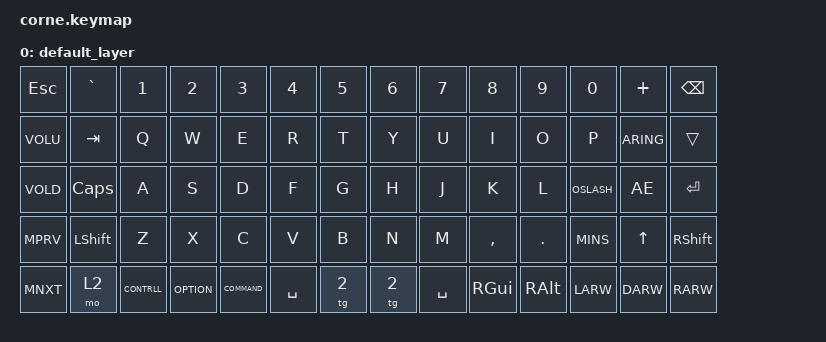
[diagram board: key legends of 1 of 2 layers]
/*
 * Copyright (c) 2020 The ZMK Contributors
 *
 * SPDX-License-Identifier: MIT
 */

#include <behaviors.dtsi>
#include <dt-bindings/zmk/keys.h>
#include <dt-bindings/zmk/bt.h>

#include <behaviors.dtsi>
#include <dt-bindings/zmk/keys.h>
#include <dt-bindings/zmk/bt.h>

/ {
        keymap {
                compatible = "zmk,keymap";

                default_layer {
// ------------------------------------------------------------------------------------------------------------
|      |      |      |      |      |      |      |   void   |      |      |      |      |      |      |      |
|      |      |      |      |      |      |      |   void   |      |      |      |      |      |      |      |
|      |      |      |      |      |      |      |   void   |      |      |      |      |      |      |      |
|      |      |      |      |      |      |      |   void   |      |      |      |      |      |      |      |
|      |      |      |      |      |      |      |   void   |      |      |      |      |      |      |      |
// ------------------------------------------------------------------------------------------------------------

//
// ------------------------------------------------------------------------------------------------------------
|  ESC   |   '    |  N1   |  n2   |  n3   |  n4   |  n5   |   void   |  n6    |  n7   |  n8   |  n9   |  n0   |   +   |  BKSP   |
| VOLU   |  Tab   |   Q   |   W   |   E   |   R   |   T   |   void   |   Y    |   U   |   I   |   O   |   P   |   Å   | trans   |
| VOLD   |  Caps  |   A   |   S   |   D   |   F   |   G   |   void   |   H    |   J   |   K   |   L   |   Ø   |   Æ   | ENTER   |
| MPRV   | LSHIFT |   Z   |   X   |   C   |   V   |   B   |   void   |   N    |   M   |KP_COMMA|KP_DOT|MINUS  |   UP  | RSHIFT |
| MNXT   |fn(&mo2)|contrll| option|command| space |layer(&tg2)|  void  |layer(&tg2)| space |CMD(RGUI)|option(RALT)|LEFT|DOWN|RIGHT|
 // ------------------------------------------------------------------------------------------------------------

How it’s broken down:


                        bindings = <
  &kp ESC     &kp GRAVE   &kp N1     &kp N2     &kp N3     &kp N4     &kp N5          &kp N6     &kp N7     &kp N8     &kp N9     &kp N0     &kp PLUS   &kp BSPC
  &kp VOLU    &kp TAB     &kp Q      &kp W      &kp E      &kp R      &kp T           &kp Y      &kp U      &kp I      &kp O      &kp P      &kp ARING &trans
  &kp VOLD    &kp CAPS    &kp A      &kp S      &kp D      &kp F      &kp G           &kp H      &kp J      &kp K      &kp L      &kp OSLASH &kp AE    &kp RET
  &kp MPRV    &kp LSHFT   &kp Z      &kp X      &kp C      &kp V      &kp B           &kp N      &kp M      &kp COMMA  &kp DOT    &kp MINS   &kp UP    &kp RSHFT
  &kp MNXT    &mo 2       &kp CONTRLL&kp OPTION &kp COMMAND&kp SPACE  &tg 2          &tg 2     &kp SPACE  &kp RGUI   &kp RALT   &kp LARW   &kp DARW  &kp RARW
>

                        >;
                };
                lower_layer {
// ------------------------------------------------------------------------------------------------------------
// |       |  BT1  |  BT2  |  BT3  |  BT4  |  BT5  |          |       |       |       |       |       | BTCLR |
// |       |       |       |       |       |       |          |       |       |       |       |       |       |
// |       |       |       | LPAR  | RPAR  |       |          |       | LBKT  | RBKT  |       |       |       |
// |       |       |       |       |       |       |          |       |       |       |       |       |       |
                        bindings = <
   &trans    &bt BT_SEL 0   &bt BT_SEL 1   &bt BT_SEL 2   &bt BT_SEL 3   &bt BT_SEL 4           &trans    &trans    &trans   &trans   &trans  &bt BT_CLR
   &trans    &trans         &trans         &trans         &trans         &trans                 &trans    &trans    &trans   &trans   &trans  &trans
   &trans    &trans         &trans         &kp LPAR       &kp RPAR       &trans                 &trans    &kp LBKT  &kp RBKT &kp MINUS   &kp EQUAL  &trans
   &trans    &trans         &trans         &trans         &trans         &trans                 &trans    &trans    &trans   &trans   &trans  &trans
                        >;
                };
        };
};
